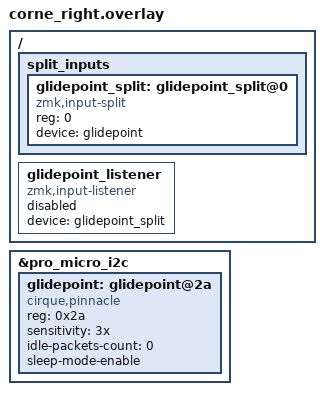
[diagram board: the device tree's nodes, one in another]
&pro_micro_i2c {
	status = "okay";

	glidepoint: glidepoint@2a {
		compatible = "cirque,pinnacle";
		reg = <0x2a>;
		status = "okay";
		sensitivity = "3x";
		idle-packets-count = <0>;
		sleep-mode-enable;
	};
};

/ {
	split_inputs {
		#address-cells = <1>;
		#size-cells = <0>;

		glidepoint_split: glidepoint_split@0 {
			compatible = "zmk,input-split";
			reg = <0>;
			device = <&glidepoint>;
		};
	};

	glidepoint_listener: glidepoint_listener {
		compatible = "zmk,input-listener";
		status = "disabled";
		device = <&glidepoint_split>;
	};
};
